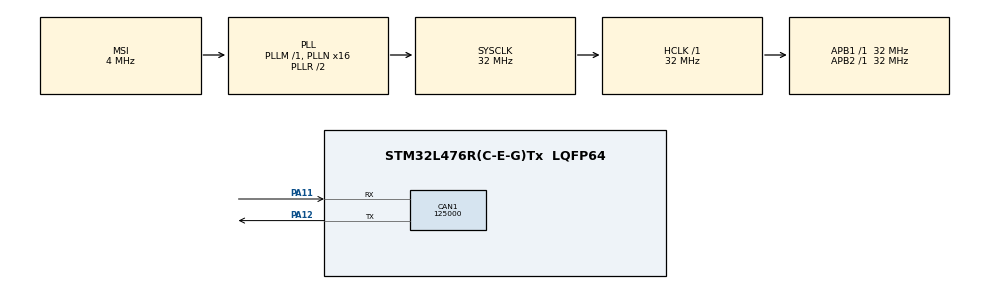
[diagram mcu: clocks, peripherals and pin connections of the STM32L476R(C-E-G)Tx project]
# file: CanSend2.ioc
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CAN1.BS1=CAN_BS1_13TQ
CAN1.BS2=CAN_BS2_2TQ
CAN1.CalculateBaudRate=125000
CAN1.CalculateTimeBit=8000
CAN1.CalculateTimeQuantum=500.0
Mcu.Family=STM32L4
Mcu.Name=STM32L476R(C-E-G)Tx
Mcu.Package=LQFP64
NVIC.PriorityGroup=NVIC_PRIORITYGROUP_4
PA11.Mode=CAN_Activate
PA11.Signal=CAN1_RX
PA12.Mode=CAN_Activate
PA12.Signal=CAN1_TX
PA13\ (JTMS-SWDIO).Mode=Serial_Wire
PA13\ (JTMS-SWDIO).Signal=SYS_JTMS-SWDIO
PA14\ (JTCK-SWCLK).Mode=Serial_Wire
PA14\ (JTCK-SWCLK).Signal=SYS_JTCK-SWCLK
PH0-OSC_IN\ (PH0).Mode=HSE-External-Oscillator
PH0-OSC_IN\ (PH0).Signal=RCC_OSC_IN
PH1-OSC_OUT\ (PH1).Mode=HSE-External-Oscillator
PH1-OSC_OUT\ (PH1).Signal=RCC_OSC_OUT
ProjectManager.HeapSize=0x200
ProjectManager.StackSize=0x400
ProjectManager.TargetToolchain=STM32CubeIDE
RCC.AHBFreq_Value=32000000
RCC.APB1Freq_Value=32000000
RCC.APB1TimFreq_Value=32000000
RCC.APB2Freq_Value=32000000
RCC.APB2TimFreq_Value=32000000
RCC.CortexFreq_Value=32000000
RCC.HCLKFreq_Value=32000000
RCC.HSE_VALUE=8000000
RCC.HSI_VALUE=16000000
RCC.LSE_VALUE=32768
RCC.MSI_VALUE=4000000
RCC.PLLN=16
RCC.SYSCLKFreq_VALUE=32000000
RCC.SYSCLKSource=RCC_SYSCLKSOURCE_PLLCLK
RCC.VCOOutputFreq_Value=64000000
board=custom

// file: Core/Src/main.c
/* USER CODE BEGIN Header */
/**
  ******************************************************************************
  * @file           : main.c
  * @brief          : Main program body
  ******************************************************************************
  * @attention
  *
  * Copyright (c) 2025 STMicroelectronics.
  * All rights reserved.
  *
  * This software is licensed under terms that can be found in the LICENSE file
  * in the root directory of this software component.
  * If no LICENSE file comes with this software, it is provided AS-IS.
  *
  ******************************************************************************
  */
/* USER CODE END Header */
#include "main.h"

/* USER CODE BEGIN Includes */
#include <string.h>
#include <stdio.h>
/* USER CODE END Includes */

CAN_HandleTypeDef hcan1;

/* USER CODE BEGIN PV */
CAN_TxHeaderTypeDef TxHeader;
uint8_t TxData[8];
uint32_t TxMailbox;
/* USER CODE END PV */

void SystemClock_Config(void);
static void MX_GPIO_Init(void);
static void MX_CAN1_Init(void);

/* USER CODE BEGIN 0 */
/* USER CODE BEGIN 0 */
int _write(int file, char *ptr, int len) {
    for (int i = 0; i < len; i++) {
        ITM_SendChar(ptr[i]);
    }
    return len;
}

// Function to print CAN frame fields in SWV
void PrintCANFrame(CAN_TxHeaderTypeDef *header, uint8_t *data) {
    // SOF
    printf("SOF: 0\n");

    // Identifier (11 bits)
    printf("ID: 0x%03X (%11b)\n", header->StdId, header->StdId);

    // RTR
    printf("RTR: %d\n", header->RTR == CAN_RTR_DATA ? 0 : 1);

    // IDE
    printf("IDE: %d\n", header->IDE == CAN_ID_STD ? 0 : 1);

    // Reserved bit
    printf("r0: 0\n");

    // DLC
    printf("DLC: %d (%04b)\n", header->DLC, header->DLC);

    // Data (if any)
    if (header->DLC > 0) {
        printf("Data: ");
        for (int i = 0; i < header->DLC; i++) {
            printf("0x%02X ", data[i]);
        }
        printf("\n");
    }

    // CRC (simulated, HAL computes this)
    printf("CRC: [Computed by HAL]\n");

    // ACK (not set in this setup, but shown for format)
    printf("ACK: [No ACK without transceiver]\n");

    // EOF
    printf("EOF: 1111111\n");
}
/* USER CODE END 0 */
/* USER CODE END 0 */

int main(void)
{

  /* MCU Configuration--------------------------------------------------------*/

  /* Reset of all peripherals, Initializes the Flash interface and the Systick. */
  HAL_Init();

  /* Configure the system clock */
  SystemClock_Config();

  /* Initialize all configured peripherals */
  MX_GPIO_Init();
  MX_CAN1_Init();
  /* USER CODE BEGIN 2 */
  if (HAL_CAN_Start(&hcan1) != HAL_OK) {
          Error_Handler();
      }

      // Configure CAN frame
      TxHeader.StdId = 0x123;
      TxHeader.ExtId = 0;
      TxHeader.IDE = CAN_ID_STD;
      TxHeader.RTR = CAN_RTR_DATA;
      TxHeader.DLC = 8;
      TxHeader.TransmitGlobalTime = DISABLE;

      TxData[0] = 0xAA;
      TxData[1] = 0xBB;
      TxData[2] = 0xCC;
      TxData[3] = 0xDD;
      TxData[4] = 0xEE;
      TxData[5] = 0xFF;
      TxData[6] = 0x00;
      TxData[7] = 0x11;
  /* USER CODE END 2 */

  /* Infinite loop */
  /* USER CODE BEGIN WHILE */
  while (1)
  {
	  if (HAL_CAN_AddTxMessage(&hcan1, &TxHeader, TxData, &TxMailbox) == HAL_OK) {
	              printf("CAN Frame Queued:\n");
	              PrintCANFrame(&TxHeader, TxData);
	          } else {
	              printf("CAN Queue Failed: Error=0x%lX\n", HAL_CAN_GetError(&hcan1));
	              HAL_CAN_ResetError(&hcan1);
	              HAL_CAN_Init(&hcan1);
	              HAL_CAN_Start(&hcan1);
	          }

	          HAL_Delay(1000);
  }
}

void SystemClock_Config(void)
{
  RCC_OscInitTypeDef RCC_OscInitStruct = {0};
  RCC_ClkInitTypeDef RCC_ClkInitStruct = {0};

  /** Configure the main internal regulator output voltage
  */
  if (HAL_PWREx_ControlVoltageScaling(PWR_REGULATOR_VOLTAGE_SCALE1) != HAL_OK)
  {
    Error_Handler();
  }

  /** Initializes the RCC Oscillators according to the specified parameters
  * in the RCC_OscInitTypeDef structure.
  */
  RCC_OscInitStruct.OscillatorType = RCC_OSCILLATORTYPE_MSI;
  RCC_OscInitStruct.MSIState = RCC_MSI_ON;
  RCC_OscInitStruct.MSICalibrationValue = 0;
  RCC_OscInitStruct.MSIClockRange = RCC_MSIRANGE_6;
  RCC_OscInitStruct.PLL.PLLState = RCC_PLL_ON;
  RCC_OscInitStruct.PLL.PLLSource = RCC_PLLSOURCE_MSI;
  RCC_OscInitStruct.PLL.PLLM = 1;
  RCC_OscInitStruct.PLL.PLLN = 16;
  RCC_OscInitStruct.PLL.PLLP = RCC_PLLP_DIV7;
  RCC_OscInitStruct.PLL.PLLQ = RCC_PLLQ_DIV2;
  RCC_OscInitStruct.PLL.PLLR = RCC_PLLR_DIV2;
  if (HAL_RCC_OscConfig(&RCC_OscInitStruct) != HAL_OK)
  {
    Error_Handler();
  }

  /** Initializes the CPU, AHB and APB buses clocks
  */
  RCC_ClkInitStruct.ClockType = RCC_CLOCKTYPE_HCLK|RCC_CLOCKTYPE_SYSCLK
                              |RCC_CLOCKTYPE_PCLK1|RCC_CLOCKTYPE_PCLK2;
  RCC_ClkInitStruct.SYSCLKSource = RCC_SYSCLKSOURCE_PLLCLK;
  RCC_ClkInitStruct.AHBCLKDivider = RCC_SYSCLK_DIV1;
  RCC_ClkInitStruct.APB1CLKDivider = RCC_HCLK_DIV1;
  RCC_ClkInitStruct.APB2CLKDivider = RCC_HCLK_DIV1;

  if (HAL_RCC_ClockConfig(&RCC_ClkInitStruct, FLASH_LATENCY_1) != HAL_OK)
  {
    Error_Handler();
  }
}

static void MX_CAN1_Init(void)
{

  hcan1.Instance = CAN1;
  hcan1.Init.Prescaler = 16;
  hcan1.Init.Mode = CAN_MODE_NORMAL;
  hcan1.Init.SyncJumpWidth = CAN_SJW_1TQ;
  hcan1.Init.TimeSeg1 = CAN_BS1_13TQ;
  hcan1.Init.TimeSeg2 = CAN_BS2_2TQ;
  hcan1.Init.TimeTriggeredMode = DISABLE;
  hcan1.Init.AutoBusOff = DISABLE;
  hcan1.Init.AutoWakeUp = DISABLE;
  hcan1.Init.AutoRetransmission = DISABLE;
  hcan1.Init.ReceiveFifoLocked = DISABLE;
  hcan1.Init.TransmitFifoPriority = DISABLE;
  if (HAL_CAN_Init(&hcan1) != HAL_OK)
  {
    Error_Handler();
  }

}

static void MX_GPIO_Init(void)
{

  /* GPIO Ports Clock Enable */
  __HAL_RCC_GPIOH_CLK_ENABLE();
  __HAL_RCC_GPIOA_CLK_ENABLE();

}

void Error_Handler(void)
{
  __disable_irq();
  while (1)
  {
  }
}
